# STM32L4P5ZGT6P register map
File version: 1.0
Registers are 32-bit, access not given, reset 0x0 unless marked. A register's access mark holds for its fields unless they carry their own. Offsets are from the block's base; [hi:lo] are bit positions; {n}, {i} and the like mark numbered series; 'fields as' and 'values as' point back to an identical list.

## DMAMUX1
Base 0x40020800
0x00 CCR0
0x04 CCR1
0x08 CCR2
0x0C CCR3
{0x0+4i} CCR{i} (i=4..9)
0x28 CCR0
0x2C CCR1
0x30 CCR2
0x34 CCR3
0x80 CCRs
0x100 CCR0
0x104 CCR1
0x108 CCR2
0x10C CCR3
0x140 CCRs

## FLASH
Base 0x40022000
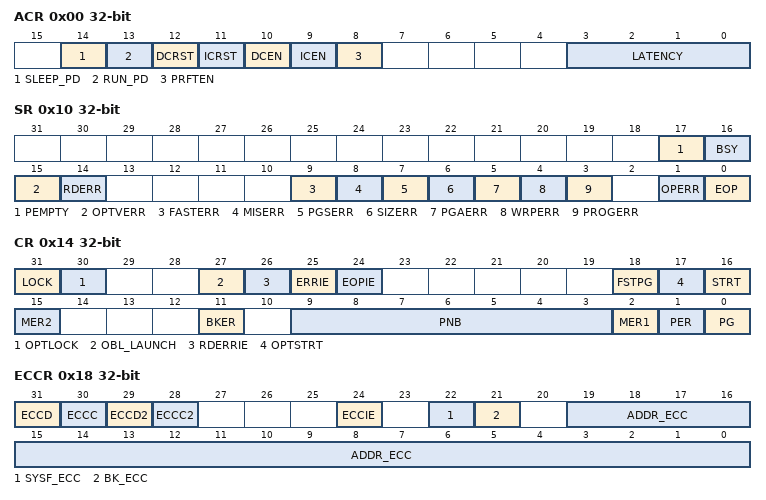
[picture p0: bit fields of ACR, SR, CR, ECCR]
0x00 ACR
  [14] SLEEP_PD, [13] RUN_PD, [12] DCRST, [11] ICRST, [10] DCEN, [9] ICEN, [8] PRFTEN, [3:0] LATENCY
0x04 PDKEYR
0x08 KEYR
0x0C OPTKEYR
0x10 SR
  [17] PEMPTY, [16] BSY, [15] OPTVERR, [14] RDERR, [9] FASTERR, [8] MISERR, [7] PGSERR, [6] SIZERR, [5] PGAERR, [4] WRPERR, [3] PROGERR, [1] OPERR, [0] EOP
0x14 CR
  [31] LOCK, [30] OPTLOCK, [27] OBL_LAUNCH, [26] RDERRIE, [25] ERRIE, [24] EOPIE, [18] FSTPG, [17] OPTSTRT, [16] STRT, [15] MER2, [11] BKER, [9:3] PNB, [2] MER1, [1] PER, [0] PG
0x18 ECCR
  [31] ECCD, [30] ECCC, [29] ECCD2, [28] ECCC2, [24] ECCIE, [22] SYSF_ECC, [21] BK_ECC, [19:0] ADDR_ECC
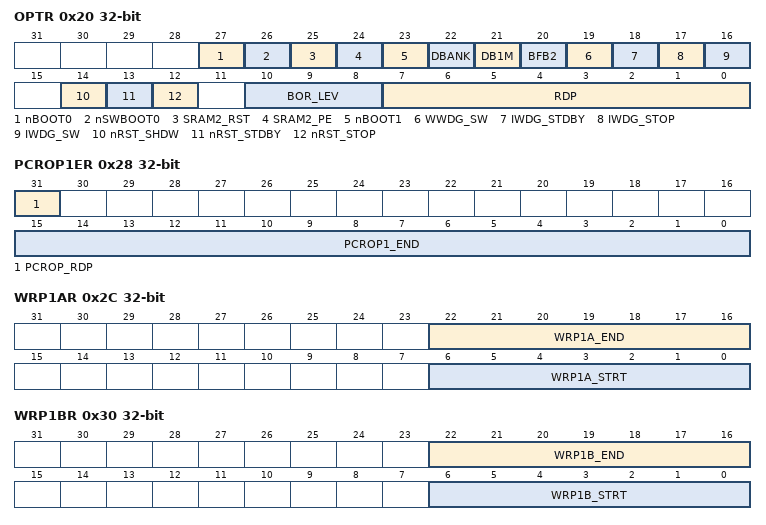
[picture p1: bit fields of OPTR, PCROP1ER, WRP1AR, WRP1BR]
0x20 OPTR
  [27] nBOOT0, [26] nSWBOOT0, [25] SRAM2_RST, [24] SRAM2_PE, [23] nBOOT1, [22] DBANK, [21] DB1M, [20] BFB2, [19] WWDG_SW, [18] IWDG_STDBY, [17] IWDG_STOP, [16] IWDG_SW, [14] nRST_SHDW, [13] nRST_STDBY, [12] nRST_STOP, [10:8] BOR_LEV, [7:0] RDP
0x24 PCROP1SR
  [15:0] PCROP1_STRT
0x28 PCROP1ER
  [31] PCROP_RDP, [15:0] PCROP1_END
0x2C WRP1AR
  [22:16] WRP1A_END, [6:0] WRP1A_STRT
0x30 WRP1BR
  [22:16] WRP1B_END, [6:0] WRP1B_STRT
0x44 PCROP2SR
  [15:0] PCROP2_STRT
0x48 PCROP2ER
  [15:0] PCROP2_END
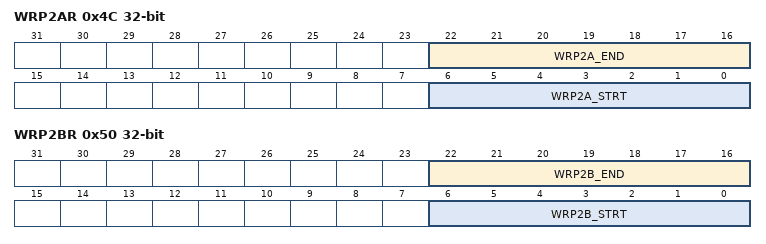
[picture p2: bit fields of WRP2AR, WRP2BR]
0x4C WRP2AR
  [22:16] WRP2A_END, [6:0] WRP2A_STRT
0x50 WRP2BR
  [22:16] WRP2B_END, [6:0] WRP2B_STRT
0x130 CFGR
  [0] LVEN
0x200 DSR

## CRC
Base 0x40023000
0x00 DR
0x04 IDR
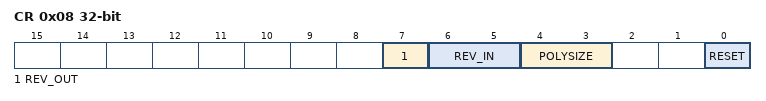
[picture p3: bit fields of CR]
0x08 CR
  [7] REV_OUT, [6:5] REV_IN, [4:3] POLYSIZE, [0] RESET
0x10 INIT
0x14 POL

## TSC
Base 0x40024000
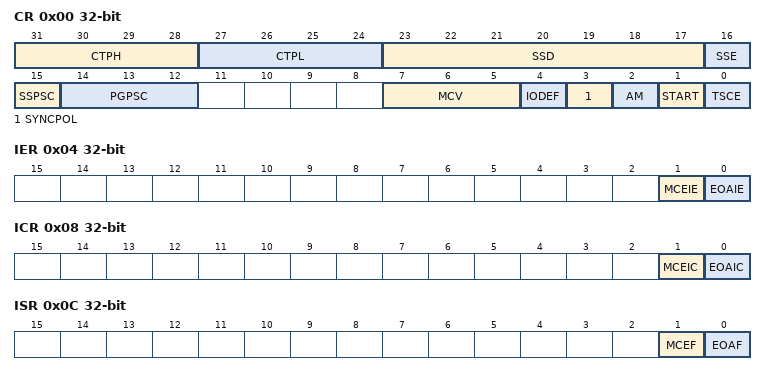
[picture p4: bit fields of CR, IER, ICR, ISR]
0x00 CR
  [31:28] CTPH, [27:24] CTPL, [23:17] SSD, [16] SSE, [15] SSPSC, [14:12] PGPSC, [7:5] MCV, [4] IODEF, [3] SYNCPOL, [2] AM, [1] START, [0] TSCE
0x04 IER
  [1] MCEIE, [0] EOAIE
0x08 ICR
  [1] MCEIC, [0] EOAIC
0x0C ISR
  [1] MCEF, [0] EOAF
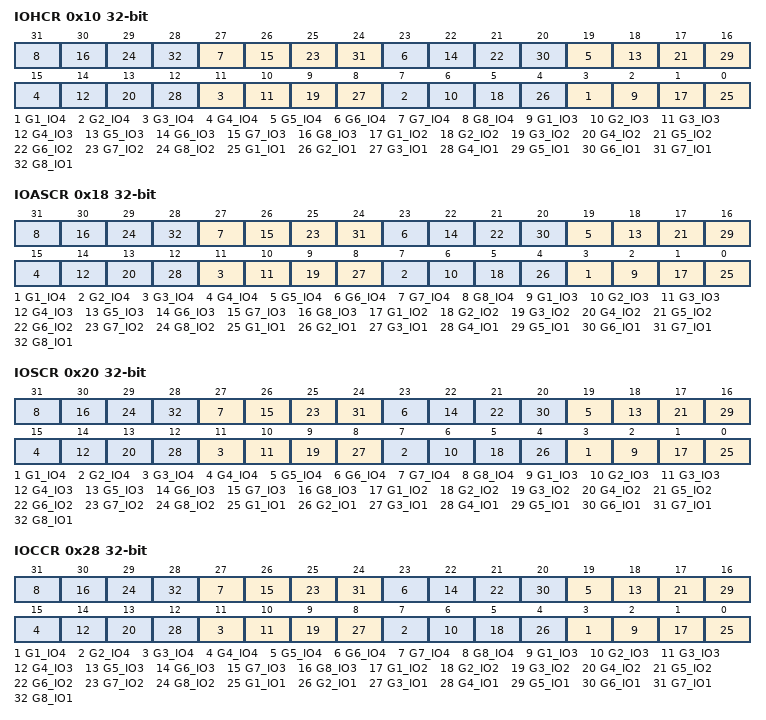
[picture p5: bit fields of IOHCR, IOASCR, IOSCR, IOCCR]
0x10 IOHCR
  [4n-1] G{n}_IO4 (n=1..8), [4n-2] G{n}_IO3 (n=1..8), [4n-3] G{n}_IO2 (n=1..8), [4n-4] G{n}_IO1 (n=1..8)
0x18 IOASCR
  fields as IOHCR
0x20 IOSCR
  fields as IOHCR
0x28 IOCCR
  fields as IOHCR
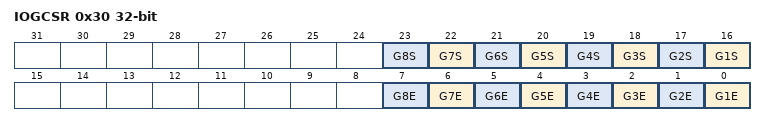
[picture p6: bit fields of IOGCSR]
0x30 IOGCSR
  [n+15] G{n}S (n=1..8), [n-1] G{n}E (n=1..8)
0x34 IOGXCR.0
  [13:0] CNT
0x38 IOGXCR.1
  [13:0] CNT
0x3C IOGXCR.2
  [13:0] CNT
0x40 IOGXCR.3
  [13:0] CNT
0x44 IOGXCR.4
  [13:0] CNT
0x48 IOGXCR.5
  [13:0] CNT
0x4C IOGXCR.6
  [13:0] CNT
0x50 IOGXCR.7
  [13:0] CNT

## GPIOA
Base 0x48000000
Same registers: GPIOB 0x48000400, GPIOC 0x48000800, GPIOD 0x48000C00, GPIOE 0x48001000, GPIOF 0x48001400, GPIOG 0x48001800, GPIOH 0x48001C00, GPIOI 0x48002000
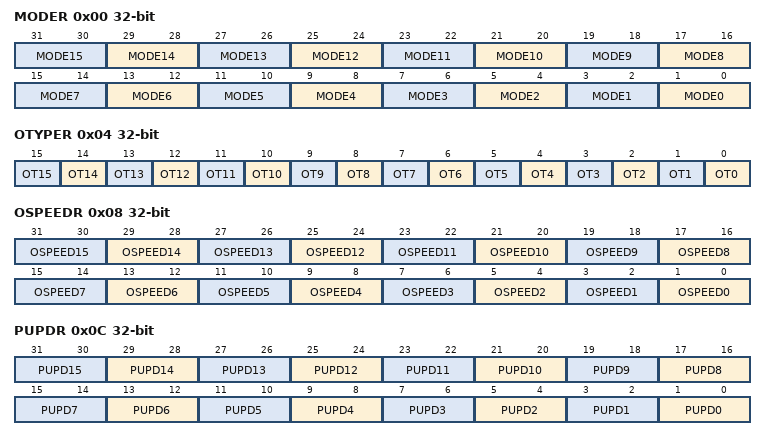
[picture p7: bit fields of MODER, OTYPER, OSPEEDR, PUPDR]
0x00 MODER
  [2n+1:2n] MODE{n} (n=0..15)
0x04 OTYPER
  [n] OT{n} (n=0..15)
0x08 OSPEEDR
  [2n+1:2n] OSPEED{n} (n=0..15)
0x0C PUPDR
  [2n+1:2n] PUPD{n} (n=0..15)
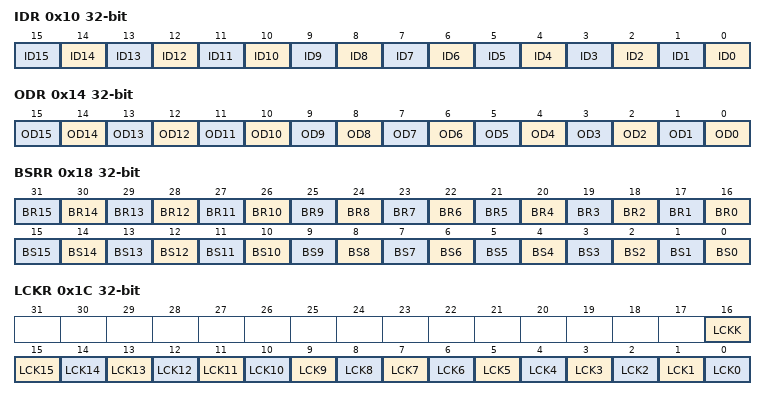
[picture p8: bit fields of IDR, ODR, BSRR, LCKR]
0x10 IDR
  [n] ID{n} (n=0..15)
0x14 ODR
  [n] OD{n} (n=0..15)
0x18 BSRR
  [n+16] BR{n} (n=0..15), [n] BS{n} (n=0..15)
0x1C LCKR
  [16] LCKK, [n] LCK{n} (n=0..15)
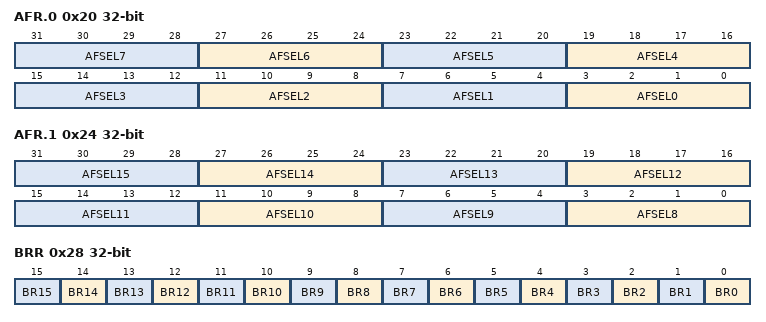
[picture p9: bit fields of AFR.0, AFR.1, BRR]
0x20 AFR.0
  [4n+3:4n] AFSEL{n} (n=0..7)
0x24 AFR.1
  [4n-29:4n-32] AFSEL{n} (n=8..15)
0x28 BRR
  [n] BR{n} (n=0..15)

## USB_OTG_FS
Base 0x50000000
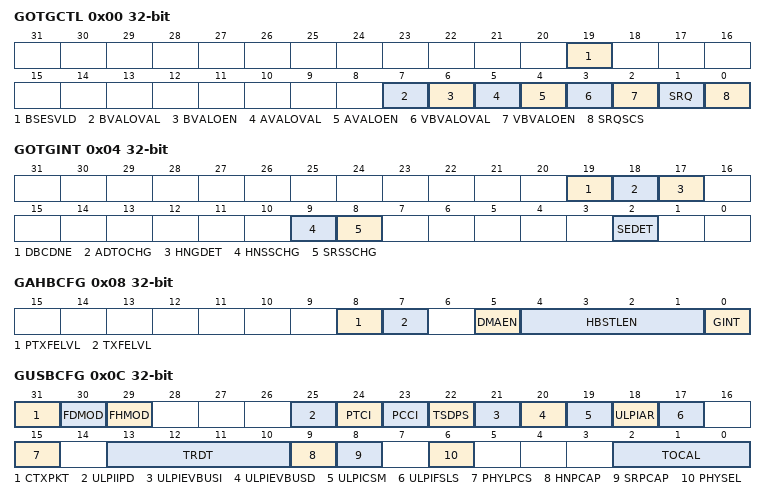
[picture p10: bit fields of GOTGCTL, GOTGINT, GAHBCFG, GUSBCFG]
0x00 GOTGCTL
  [19] BSESVLD, [7] BVALOVAL, [6] BVALOEN, [5] AVALOVAL, [4] AVALOEN, [3] VBVALOVAL, [2] VBVALOEN, [1] SRQ, [0] SRQSCS
0x04 GOTGINT
  [19] DBCDNE, [18] ADTOCHG, [17] HNGDET, [9] HNSSCHG, [8] SRSSCHG, [2] SEDET
0x08 GAHBCFG
  [8] PTXFELVL, [7] TXFELVL, [5] DMAEN, [4:1] HBSTLEN, [0] GINT
0x0C GUSBCFG
  [31] CTXPKT, [30] FDMOD, [29] FHMOD, [25] ULPIIPD, [24] PTCI, [23] PCCI, [22] TSDPS, [21] ULPIEVBUSI, [20] ULPIEVBUSD, [19] ULPICSM, [18] ULPIAR, [17] ULPIFSLS, [15] PHYLPCS, [13:10] TRDT, [9] HNPCAP, [8] SRPCAP, [6] PHYSEL, [2:0] TOCAL
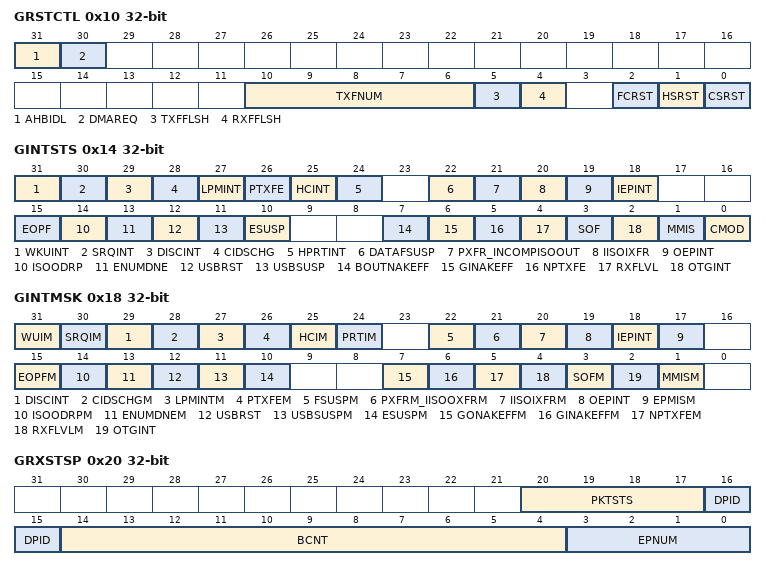
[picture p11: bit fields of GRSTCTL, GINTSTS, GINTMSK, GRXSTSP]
0x10 GRSTCTL
  [31] AHBIDL, [30] DMAREQ, [10:6] TXFNUM, [5] TXFFLSH, [4] RXFFLSH, [2] FCRST, [1] HSRST, [0] CSRST
0x14 GINTSTS
  [31] WKUINT, [30] SRQINT, [29] DISCINT, [28] CIDSCHG, [27] LPMINT, [26] PTXFE, [25] HCINT, [24] HPRTINT, [22] DATAFSUSP, [21] PXFR_INCOMPISOOUT, [20] IISOIXFR, [19] OEPINT, [18] IEPINT, [15] EOPF, [14] ISOODRP, [13] ENUMDNE, [12] USBRST, [11] USBSUSP, [10] ESUSP, [7] BOUTNAKEFF, [6] GINAKEFF, [5] NPTXFE, [4] RXFLVL, [3] SOF, [2] OTGINT, [1] MMIS, [0] CMOD
0x18 GINTMSK
  [31] WUIM, [30] SRQIM, [29] DISCINT, [28] CIDSCHGM, [27] LPMINTM, [26] PTXFEM, [25] HCIM, [24] PRTIM, [22] FSUSPM, [21] PXFRM_IISOOXFRM, [20] IISOIXFRM, [19] OEPINT, [18] IEPINT, [17] EPMISM, [15] EOPFM, [14] ISOODRPM, [13] ENUMDNEM, [12] USBRST, [11] USBSUSPM, [10] ESUSPM, [7] GONAKEFFM, [6] GINAKEFFM, [5] NPTXFEM, [4] RXFLVLM, [3] SOFM, [2] OTGINT, [1] MMISM
0x1C GRXSTSR
0x20 GRXSTSP
  [20:17] PKTSTS, [16:15] DPID, [14:4] BCNT, [3:0] EPNUM
0x24 GRXFSIZ
  [15:0] RXFD
0x28 DIEPTXF0_HNPTXFSIZ
0x2C HNPTXSTS
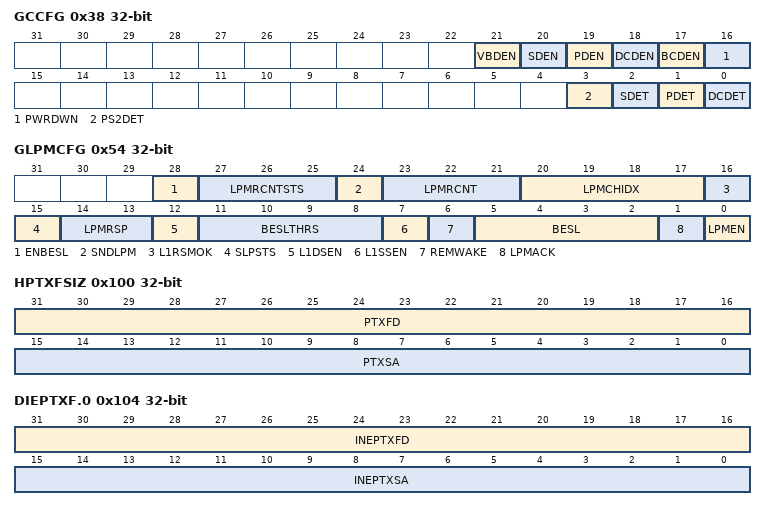
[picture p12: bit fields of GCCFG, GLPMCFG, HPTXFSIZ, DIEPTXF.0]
0x38 GCCFG
  [21] VBDEN, [20] SDEN, [19] PDEN, [18] DCDEN, [17] BCDEN, [16] PWRDWN, [3] PS2DET, [2] SDET, [1] PDET, [0] DCDET
0x3C CID
  [31:0] PRODUCT_ID
0x40 GSNPSID
{0x40+4i} GHWCFG{i} (i=1..3)
0x54 GLPMCFG
  [28] ENBESL, [27:25] LPMRCNTSTS, [24] SNDLPM, [23:21] LPMRCNT, [20:17] LPMCHIDX, [16] L1RSMOK, [15] SLPSTS, [14:13] LPMRSP, [12] L1DSEN, [11:8] BESLTHRS, [7] L1SSEN, [6] REMWAKE, [5:2] BESL, [1] LPMACK, [0] LPMEN
0x58 GPWRDN
  [6] DISABLEVBUS
0x5C GDFIFOCFG
0x60 GADPCTL
0x100 HPTXFSIZ
  [31:16] PTXFD, [15:0] PTXSA
0x104 DIEPTXF.0
  [31:16] INEPTXFD, [15:0] INEPTXSA
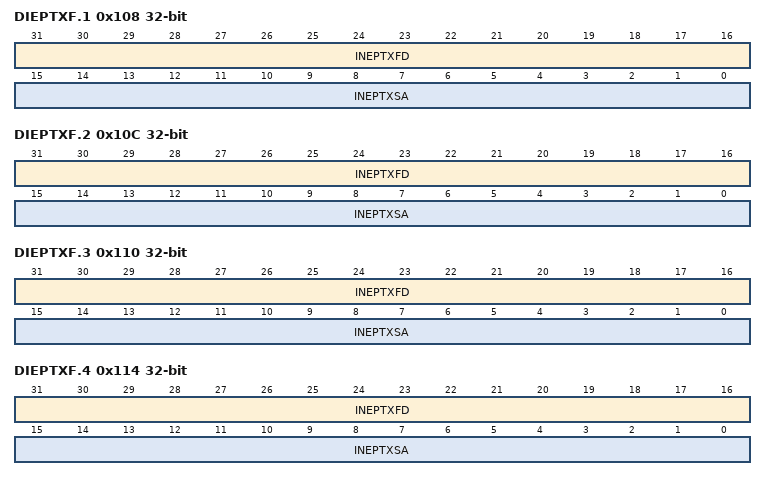
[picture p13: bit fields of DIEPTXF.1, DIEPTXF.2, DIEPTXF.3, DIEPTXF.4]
0x108 DIEPTXF.1
  [31:16] INEPTXFD, [15:0] INEPTXSA
0x10C DIEPTXF.2
  [31:16] INEPTXFD, [15:0] INEPTXSA
0x110 DIEPTXF.3
  [31:16] INEPTXFD, [15:0] INEPTXSA
0x114 DIEPTXF.4
  [31:16] INEPTXFD, [15:0] INEPTXSA
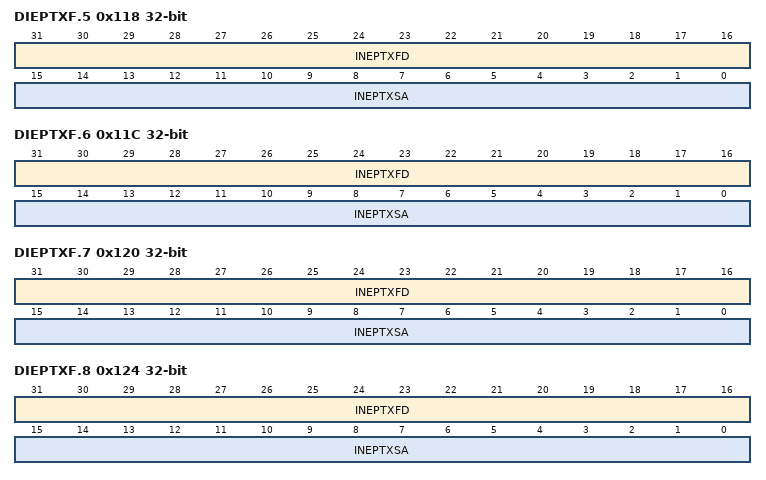
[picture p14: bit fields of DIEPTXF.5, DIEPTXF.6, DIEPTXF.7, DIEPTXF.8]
0x118 DIEPTXF.5
  [31:16] INEPTXFD, [15:0] INEPTXSA
0x11C DIEPTXF.6
  [31:16] INEPTXFD, [15:0] INEPTXSA
0x120 DIEPTXF.7
  [31:16] INEPTXFD, [15:0] INEPTXSA
0x124 DIEPTXF.8
  [31:16] INEPTXFD, [15:0] INEPTXSA
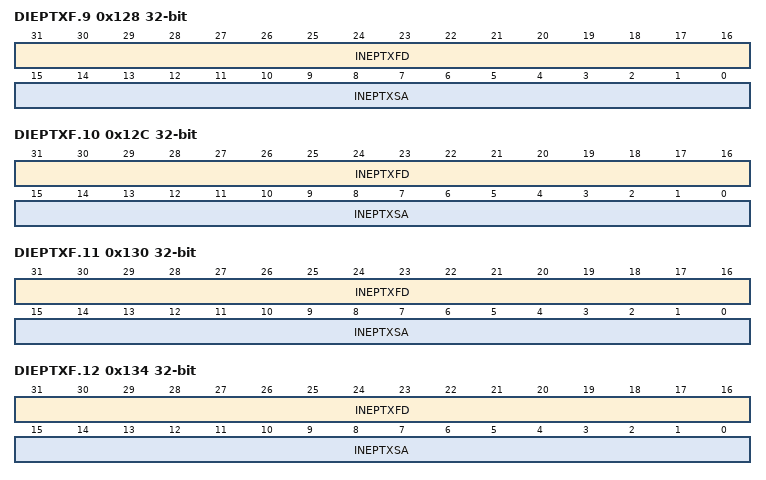
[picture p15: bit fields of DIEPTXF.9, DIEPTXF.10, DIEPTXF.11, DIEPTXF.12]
0x128 DIEPTXF.9
  [31:16] INEPTXFD, [15:0] INEPTXSA
0x12C DIEPTXF.10
  [31:16] INEPTXFD, [15:0] INEPTXSA
0x130 DIEPTXF.11
  [31:16] INEPTXFD, [15:0] INEPTXSA
0x134 DIEPTXF.12
  [31:16] INEPTXFD, [15:0] INEPTXSA
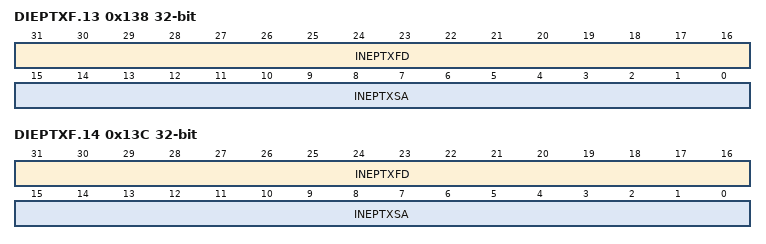
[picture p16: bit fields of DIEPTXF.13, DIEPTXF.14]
0x138 DIEPTXF.13
  [31:16] INEPTXFD, [15:0] INEPTXSA
0x13C DIEPTXF.14
  [31:16] INEPTXFD, [15:0] INEPTXSA
